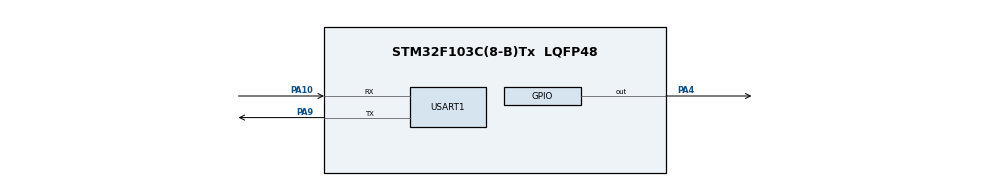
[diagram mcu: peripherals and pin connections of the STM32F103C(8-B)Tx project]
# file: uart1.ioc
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Mcu.Family=STM32F1
Mcu.Name=STM32F103C(8-B)Tx
Mcu.Package=LQFP48
NVIC.PriorityGroup=NVIC_PRIORITYGROUP_4
NVIC.USART1_IRQn=true\:0\:0\:false\:false\:true\:true\:true\:true
PA10.Mode=Asynchronous
PA10.Signal=USART1_RX
PA13.Mode=Serial_Wire
PA13.Signal=SYS_JTMS-SWDIO
PA14.Mode=Serial_Wire
PA14.Signal=SYS_JTCK-SWCLK
PA4.Signal=GPIO_Output
PA9.Mode=Asynchronous
PA9.Signal=USART1_TX
PC14-OSC32_IN.Mode=LSE-External-Oscillator
PC14-OSC32_IN.Signal=RCC_OSC32_IN
PC15-OSC32_OUT.Mode=LSE-External-Oscillator
PC15-OSC32_OUT.Signal=RCC_OSC32_OUT
PD0-OSC_IN.Mode=HSE-External-Oscillator
PD0-OSC_IN.Signal=RCC_OSC_IN
PD1-OSC_OUT.Mode=HSE-External-Oscillator
PD1-OSC_OUT.Signal=RCC_OSC_OUT
ProjectManager.HeapSize=0x200
ProjectManager.StackSize=0x400
ProjectManager.TargetToolchain=MDK-ARM V5
RCC.AHBFreq_Value=16000000
RCC.APB1Freq_Value=16000000
RCC.APB1TimFreq_Value=16000000
RCC.APB2Freq_Value=16000000
RCC.APB2TimFreq_Value=16000000
RCC.HCLKFreq_Value=16000000
RCC.PLLSourceVirtual=RCC_PLLSOURCE_HSE
RCC.SYSCLKFreq_VALUE=16000000
RCC.SYSCLKSource=RCC_SYSCLKSOURCE_PLLCLK
RCC.USBFreq_Value=16000000
USART1.VirtualMode=VM_ASYNC
board=custom

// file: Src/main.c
/* USER CODE BEGIN Header */
/**
  ******************************************************************************
  * @file           : main.c
  * @brief          : Main program body
  ******************************************************************************
  * @attention
  *
  * Copyright (c) 2024 STMicroelectronics.
  * All rights reserved.
  *
  * This software is licensed under terms that can be found in the LICENSE file
  * in the root directory of this software component.
  * If no LICENSE file comes with this software, it is provided AS-IS.
  *
  ******************************************************************************
  */
/* USER CODE END Header */

#include "main.h"
#include "usart.h"
#include "gpio.h"
#include <string.h>

/* USER CODE BEGIN PV */

// 全局变量定义放在这里
uint8_t sendFlag = 1;        // 发送标志位
uint8_t rxData;              // 接收数据缓冲区
uint8_t uartRxFlag = 0;      // 接收完成标志

/* USER CODE END PV */

void SystemClock_Config(void);

/* USER CODE BEGIN 0 */

// UART接收完成回调函数放在这里
void HAL_UART_RxCpltCallback(UART_HandleTypeDef *huart)
{
  if(huart->Instance == USART1)
  {
    uartRxFlag = 1;  // 设置接收完成标志
  }
}

/* USER CODE END 0 */

int main(void)
{

  /* MCU Configuration--------------------------------------------------------*/

  /* Reset of all peripherals, Initializes the Flash interface and the Systick. */
  HAL_Init();

  /* Configure the system clock */
  SystemClock_Config();

  /* Initialize all configured peripherals */
  MX_GPIO_Init();
  MX_USART1_UART_Init();
  /* USER CODE BEGIN 2 */

  // 启动UART接收中断 - 放在外设初始化之后
  HAL_UART_Receive_IT(&huart1, &rxData, 1);

  /* USER CODE END 2 */

  /* Infinite loop */
  while (1)
  {

    /* USER CODE BEGIN 3 */

    // 检查是否收到数据
    if(uartRxFlag)
    {
      uartRxFlag = 0;  // 清除标志

      // 处理接收到的数据
      if(rxData == '#')
      {
        sendFlag = 0;  // 暂停发送
      }
      else if(rxData == '*')
      {
        sendFlag = 1;  // 继续发送
      }

      // 重新启动接收中断
      HAL_UART_Receive_IT(&huart1, &rxData, 1);
    }

    // 根据标志位决定是否发送数据
    if(sendFlag)
    {
      char data[] = "hello windows!\r\n";
      HAL_UART_Transmit(&huart1, (uint8_t *)data, strlen(data), 0xFFFF);

      // LED闪烁指示
      HAL_GPIO_WritePin(GPIOA, GPIO_PIN_4, GPIO_PIN_SET);
      HAL_Delay(100);
      HAL_GPIO_WritePin(GPIOA, GPIO_PIN_4, GPIO_PIN_RESET);

      HAL_Delay(1000);  // 每秒发送一次
    }
    else
    {
      // 暂停状态时LED慢闪
      HAL_GPIO_TogglePin(GPIOA, GPIO_PIN_4);
      HAL_Delay(500);
    }
  }
  /* USER CODE END 3 */
}

void SystemClock_Config(void)
{
  // 系统时钟配置代码（由CubeMX生成）
}

/* USER CODE BEGIN 4 */

// 其他用户代码可以放在这里

/* USER CODE END 4 */

void Error_Handler(void)
{
  __disable_irq();
  while (1)
  {
  }
}
